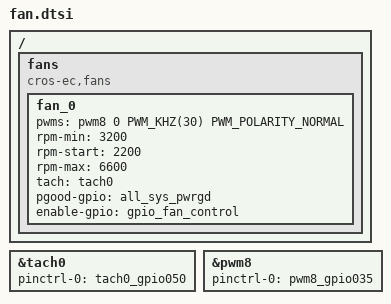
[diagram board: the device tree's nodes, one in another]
/* Copyright 2024 The ChromiumOS Authors
 * Use of this source code is governed by a BSD-style license that can be
 * found in the LICENSE file.
 */

/ {
	fans {
		compatible = "cros-ec,fans";

		fan_0 {
			pwms = <&pwm8 0 PWM_KHZ(30) PWM_POLARITY_NORMAL>;
			rpm-min = <3200>;
			rpm-start = <2200>;
			rpm-max = <6600>;
			tach = <&tach0>;
			pgood-gpio = <&all_sys_pwrgd>;
			enable-gpio = <&gpio_fan_control>;
		};
	};
};

/* Tachemeter for fan speed measurement */
&tach0 {
	status = "okay";
	pinctrl-0 = <&tach0_gpio050>; /* TACH0 input on GPI050 */
	pinctrl-names = "default";
};

&pwm8 {
	status = "okay";
	pinctrl-0 = <&pwm8_gpio035>;
	pinctrl-names = "default";
};
